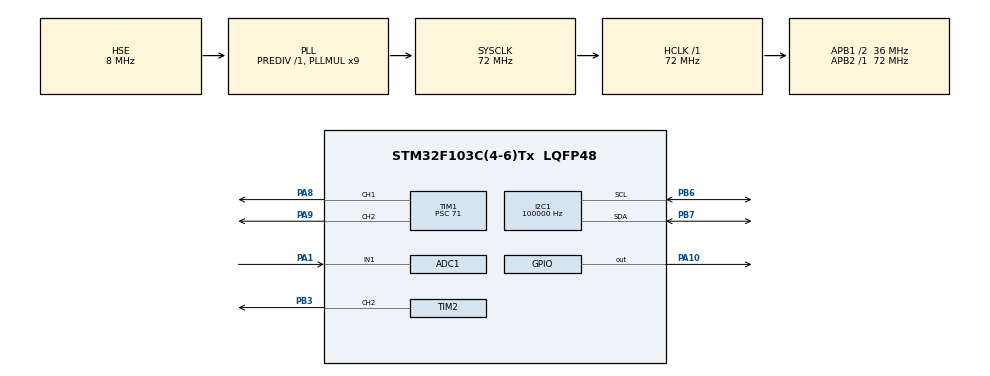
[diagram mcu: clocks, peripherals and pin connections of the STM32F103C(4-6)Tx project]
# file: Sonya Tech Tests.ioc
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ADC1.Channel-1\#ChannelRegularConversion=ADC_CHANNEL_1
ADC1.NbrOfConversionFlag=1
ADC1.Rank-1\#ChannelRegularConversion=1
ADC1.SamplingTime-1\#ChannelRegularConversion=ADC_SAMPLETIME_1CYCLE_5
ADC1.master=1
FREERTOS.Tasks01=GreenLed,-3,128,StartGreenLed,Default,NULL,Dynamic,NULL,NULL;Heater,2,128,HeaterFunction,Default,NULL,Dynamic,NULL,NULL;Cooler,0,128,CoolerFunction,Default,NULL,Dynamic,NULL,NULL
FREERTOS.configUSE_NEWLIB_REENTRANT=1
I2C1.ClockSpeed=100000
I2C1.I2C_Mode=I2C_Standard
Mcu.Family=STM32F1
Mcu.Name=STM32F103C(4-6)Tx
Mcu.Package=LQFP48
NVIC.PriorityGroup=NVIC_PRIORITYGROUP_4
NVIC.TIM3_IRQn=true\:15\:0\:false\:false\:true\:false\:false\:true\:true
NVIC.TimeBase=TIM3_IRQn
NVIC.TimeBaseIP=TIM3
PA1.Signal=ADCx_IN1
PA10.Signal=GPIO_Output
PA13.Mode=Serial_Wire
PA13.Signal=SYS_JTMS-SWDIO
PA14.Mode=Serial_Wire
PA14.Signal=SYS_JTCK-SWCLK
PA8.Signal=S_TIM1_CH1
PA9.Signal=S_TIM1_CH2
PB3.Signal=S_TIM2_CH2
PB6.GPIO_Pu=GPIO_NOPULL
PB6.Mode=I2C
PB6.Signal=I2C1_SCL
PB7.GPIO_Pu=GPIO_NOPULL
PB7.Mode=I2C
PB7.Signal=I2C1_SDA
PC14-OSC32_IN.Mode=LSE-External-Oscillator
PC14-OSC32_IN.Signal=RCC_OSC32_IN
PC15-OSC32_OUT.Mode=LSE-External-Oscillator
PC15-OSC32_OUT.Signal=RCC_OSC32_OUT
PD0-OSC_IN.Mode=HSE-External-Oscillator
PD0-OSC_IN.Signal=RCC_OSC_IN
PD1-OSC_OUT.Mode=HSE-External-Oscillator
PD1-OSC_OUT.Signal=RCC_OSC_OUT
ProjectManager.HeapSize=0x200
ProjectManager.StackSize=0x400
ProjectManager.TargetToolchain=STM32CubeIDE
RCC.ADCPresc=RCC_ADCPCLK2_DIV6
RCC.AHBFreq_Value=72000000
RCC.APB1CLKDivider=RCC_HCLK_DIV2
RCC.APB1Freq_Value=36000000
RCC.APB1TimFreq_Value=72000000
RCC.APB2Freq_Value=72000000
RCC.APB2TimFreq_Value=72000000
RCC.HCLKFreq_Value=72000000
RCC.PLLMUL=RCC_PLL_MUL9
RCC.PLLSourceVirtual=RCC_PLLSOURCE_HSE
RCC.SYSCLKFreq_VALUE=72000000
RCC.SYSCLKSource=RCC_SYSCLKSOURCE_PLLCLK
RCC.USBFreq_Value=72000000
SH.ADCx_IN1.0=ADC1_IN1,IN1
SH.S_TIM1_CH1.0=TIM1_CH1,PWM Generation1 CH1
SH.S_TIM1_CH2.0=TIM1_CH2,PWM Generation2 CH2
SH.S_TIM2_CH2.0=TIM2_CH2,PWM Generation2 CH2
TIM1.Channel-PWM\ Generation1\ CH1=TIM_CHANNEL_1
TIM1.Channel-PWM\ Generation2\ CH2=TIM_CHANNEL_2
TIM1.Period=99
TIM1.Prescaler=71
TIM2.Channel-PWM\ Generation2\ CH2=TIM_CHANNEL_2
TIM2.Period=99
TIM2.Prescaler=71
VP_FREERTOS_VS_CMSIS_V1.Mode=CMSIS_V1
VP_SYS_VS_tim3.Mode=TIM3
VP_TIM1_VS_ClockSourceINT.Mode=Internal
VP_TIM2_VS_ClockSourceINT.Mode=Internal
board=custom

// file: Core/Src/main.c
/* USER CODE BEGIN Header */
/**
  ******************************************************************************
  * @file           : main.c
  * @brief          : Main program body
  ******************************************************************************
  * @attention
  *
  * Copyright (c) 2025 STMicroelectronics.
  * All rights reserved.
  *
  * This software is licensed under terms that can be found in the LICENSE file
  * in the root directory of this software component.
  * If no LICENSE file comes with this software, it is provided AS-IS.
  *
  ******************************************************************************
  */
/* USER CODE END Header */
#include "main.h"
#include "cmsis_os.h"

/* USER CODE BEGIN Includes */

#include "heater.h"
#include "cooler.h"

/* USER CODE END Includes */

ADC_HandleTypeDef hadc1;

I2C_HandleTypeDef hi2c1;

TIM_HandleTypeDef htim1;
TIM_HandleTypeDef htim2;

osThreadId GreenLedHandle;
osThreadId HeaterHandle;
osThreadId CoolerHandle;

void SystemClock_Config(void);
static void MX_GPIO_Init(void);
static void MX_TIM1_Init(void);
static void MX_TIM2_Init(void);
static void MX_I2C1_Init(void);
static void MX_ADC1_Init(void);
void StartGreenLed(void const * argument);
void HeaterFunction(void const * argument);
void CoolerFunction(void const * argument);

int main(void)
{

  /* MCU Configuration--------------------------------------------------------*/

  /* Reset of all peripherals, Initializes the Flash interface and the Systick. */
  HAL_Init();

  /* Configure the system clock */
  SystemClock_Config();

  /* Initialize all configured peripherals */
  MX_GPIO_Init();
  MX_TIM1_Init();
  MX_TIM2_Init();
  MX_I2C1_Init();
  MX_ADC1_Init();

  /* Create the thread(s) */
  /* definition and creation of GreenLed */
  osThreadDef(GreenLed, StartGreenLed, osPriorityIdle, 0, 128);
  GreenLedHandle = osThreadCreate(osThread(GreenLed), NULL);

  /* definition and creation of Heater */
  osThreadDef(Heater, HeaterFunction, osPriorityHigh, 0, 128);
  HeaterHandle = osThreadCreate(osThread(Heater), NULL);

  /* definition and creation of Cooler */
  osThreadDef(Cooler, CoolerFunction, osPriorityNormal, 0, 128);
  CoolerHandle = osThreadCreate(osThread(Cooler), NULL);

  /* Start scheduler */
  osKernelStart();

  /* We should never get here as control is now taken by the scheduler */

  /* Infinite loop */
  while (1)
  {

  }
}

void SystemClock_Config(void)
{
  RCC_OscInitTypeDef RCC_OscInitStruct = {0};
  RCC_ClkInitTypeDef RCC_ClkInitStruct = {0};
  RCC_PeriphCLKInitTypeDef PeriphClkInit = {0};

  /** Initializes the RCC Oscillators according to the specified parameters
  * in the RCC_OscInitTypeDef structure.
  */
  RCC_OscInitStruct.OscillatorType = RCC_OSCILLATORTYPE_HSE;
  RCC_OscInitStruct.HSEState = RCC_HSE_ON;
  RCC_OscInitStruct.HSEPredivValue = RCC_HSE_PREDIV_DIV1;
  RCC_OscInitStruct.HSIState = RCC_HSI_ON;
  RCC_OscInitStruct.PLL.PLLState = RCC_PLL_ON;
  RCC_OscInitStruct.PLL.PLLSource = RCC_PLLSOURCE_HSE;
  RCC_OscInitStruct.PLL.PLLMUL = RCC_PLL_MUL9;
  if (HAL_RCC_OscConfig(&RCC_OscInitStruct) != HAL_OK)
  {
    Error_Handler();
  }

  /** Initializes the CPU, AHB and APB buses clocks
  */
  RCC_ClkInitStruct.ClockType = RCC_CLOCKTYPE_HCLK|RCC_CLOCKTYPE_SYSCLK
                              |RCC_CLOCKTYPE_PCLK1|RCC_CLOCKTYPE_PCLK2;
  RCC_ClkInitStruct.SYSCLKSource = RCC_SYSCLKSOURCE_PLLCLK;
  RCC_ClkInitStruct.AHBCLKDivider = RCC_SYSCLK_DIV1;
  RCC_ClkInitStruct.APB1CLKDivider = RCC_HCLK_DIV2;
  RCC_ClkInitStruct.APB2CLKDivider = RCC_HCLK_DIV1;

  if (HAL_RCC_ClockConfig(&RCC_ClkInitStruct, FLASH_LATENCY_2) != HAL_OK)
  {
    Error_Handler();
  }
  PeriphClkInit.PeriphClockSelection = RCC_PERIPHCLK_ADC;
  PeriphClkInit.AdcClockSelection = RCC_ADCPCLK2_DIV6;
  if (HAL_RCCEx_PeriphCLKConfig(&PeriphClkInit) != HAL_OK)
  {
    Error_Handler();
  }
}

static void MX_ADC1_Init(void)
{

  ADC_ChannelConfTypeDef sConfig = {0};

  /** Common config
  */
  hadc1.Instance = ADC1;
  hadc1.Init.ScanConvMode = ADC_SCAN_DISABLE;
  hadc1.Init.ContinuousConvMode = DISABLE;
  hadc1.Init.DiscontinuousConvMode = DISABLE;
  hadc1.Init.ExternalTrigConv = ADC_SOFTWARE_START;
  hadc1.Init.DataAlign = ADC_DATAALIGN_RIGHT;
  hadc1.Init.NbrOfConversion = 1;
  if (HAL_ADC_Init(&hadc1) != HAL_OK)
  {
    Error_Handler();
  }

  /** Configure Regular Channel
  */
  sConfig.Channel = ADC_CHANNEL_1;
  sConfig.Rank = ADC_REGULAR_RANK_1;
  sConfig.SamplingTime = ADC_SAMPLETIME_1CYCLE_5;
  if (HAL_ADC_ConfigChannel(&hadc1, &sConfig) != HAL_OK)
  {
    Error_Handler();
  }

}

static void MX_I2C1_Init(void)
{

  hi2c1.Instance = I2C1;
  hi2c1.Init.ClockSpeed = 100000;
  hi2c1.Init.DutyCycle = I2C_DUTYCYCLE_2;
  hi2c1.Init.OwnAddress1 = 0;
  hi2c1.Init.AddressingMode = I2C_ADDRESSINGMODE_7BIT;
  hi2c1.Init.DualAddressMode = I2C_DUALADDRESS_DISABLE;
  hi2c1.Init.OwnAddress2 = 0;
  hi2c1.Init.GeneralCallMode = I2C_GENERALCALL_DISABLE;
  hi2c1.Init.NoStretchMode = I2C_NOSTRETCH_DISABLE;
  if (HAL_I2C_Init(&hi2c1) != HAL_OK)
  {
    Error_Handler();
  }

}

static void MX_TIM1_Init(void)
{

  TIM_ClockConfigTypeDef sClockSourceConfig = {0};
  TIM_MasterConfigTypeDef sMasterConfig = {0};
  TIM_OC_InitTypeDef sConfigOC = {0};
  TIM_BreakDeadTimeConfigTypeDef sBreakDeadTimeConfig = {0};

  htim1.Instance = TIM1;
  htim1.Init.Prescaler = 71;
  htim1.Init.CounterMode = TIM_COUNTERMODE_UP;
  htim1.Init.Period = 99;
  htim1.Init.ClockDivision = TIM_CLOCKDIVISION_DIV1;
  htim1.Init.RepetitionCounter = 0;
  htim1.Init.AutoReloadPreload = TIM_AUTORELOAD_PRELOAD_DISABLE;
  if (HAL_TIM_Base_Init(&htim1) != HAL_OK)
  {
    Error_Handler();
  }
  sClockSourceConfig.ClockSource = TIM_CLOCKSOURCE_INTERNAL;
  if (HAL_TIM_ConfigClockSource(&htim1, &sClockSourceConfig) != HAL_OK)
  {
    Error_Handler();
  }
  if (HAL_TIM_PWM_Init(&htim1) != HAL_OK)
  {
    Error_Handler();
  }
  sMasterConfig.MasterOutputTrigger = TIM_TRGO_RESET;
  sMasterConfig.MasterSlaveMode = TIM_MASTERSLAVEMODE_DISABLE;
  if (HAL_TIMEx_MasterConfigSynchronization(&htim1, &sMasterConfig) != HAL_OK)
  {
    Error_Handler();
  }
  sConfigOC.OCMode = TIM_OCMODE_PWM1;
  sConfigOC.Pulse = 0;
  sConfigOC.OCPolarity = TIM_OCPOLARITY_HIGH;
  sConfigOC.OCNPolarity = TIM_OCNPOLARITY_HIGH;
  sConfigOC.OCFastMode = TIM_OCFAST_DISABLE;
  sConfigOC.OCIdleState = TIM_OCIDLESTATE_RESET;
  sConfigOC.OCNIdleState = TIM_OCNIDLESTATE_RESET;
  if (HAL_TIM_PWM_ConfigChannel(&htim1, &sConfigOC, TIM_CHANNEL_1) != HAL_OK)
  {
    Error_Handler();
  }
  if (HAL_TIM_PWM_ConfigChannel(&htim1, &sConfigOC, TIM_CHANNEL_2) != HAL_OK)
  {
    Error_Handler();
  }
  sBreakDeadTimeConfig.OffStateRunMode = TIM_OSSR_DISABLE;
  sBreakDeadTimeConfig.OffStateIDLEMode = TIM_OSSI_DISABLE;
  sBreakDeadTimeConfig.LockLevel = TIM_LOCKLEVEL_OFF;
  sBreakDeadTimeConfig.DeadTime = 0;
  sBreakDeadTimeConfig.BreakState = TIM_BREAK_DISABLE;
  sBreakDeadTimeConfig.BreakPolarity = TIM_BREAKPOLARITY_HIGH;
  sBreakDeadTimeConfig.AutomaticOutput = TIM_AUTOMATICOUTPUT_DISABLE;
  if (HAL_TIMEx_ConfigBreakDeadTime(&htim1, &sBreakDeadTimeConfig) != HAL_OK)
  {
    Error_Handler();
  }
  HAL_TIM_MspPostInit(&htim1);

}

static void MX_TIM2_Init(void)
{

  TIM_ClockConfigTypeDef sClockSourceConfig = {0};
  TIM_MasterConfigTypeDef sMasterConfig = {0};
  TIM_OC_InitTypeDef sConfigOC = {0};

  htim2.Instance = TIM2;
  htim2.Init.Prescaler = 71;
  htim2.Init.CounterMode = TIM_COUNTERMODE_UP;
  htim2.Init.Period = 99;
  htim2.Init.ClockDivision = TIM_CLOCKDIVISION_DIV1;
  htim2.Init.AutoReloadPreload = TIM_AUTORELOAD_PRELOAD_DISABLE;
  if (HAL_TIM_Base_Init(&htim2) != HAL_OK)
  {
    Error_Handler();
  }
  sClockSourceConfig.ClockSource = TIM_CLOCKSOURCE_INTERNAL;
  if (HAL_TIM_ConfigClockSource(&htim2, &sClockSourceConfig) != HAL_OK)
  {
    Error_Handler();
  }
  if (HAL_TIM_PWM_Init(&htim2) != HAL_OK)
  {
    Error_Handler();
  }
  sMasterConfig.MasterOutputTrigger = TIM_TRGO_RESET;
  sMasterConfig.MasterSlaveMode = TIM_MASTERSLAVEMODE_DISABLE;
  if (HAL_TIMEx_MasterConfigSynchronization(&htim2, &sMasterConfig) != HAL_OK)
  {
    Error_Handler();
  }
  sConfigOC.OCMode = TIM_OCMODE_PWM1;
  sConfigOC.Pulse = 0;
  sConfigOC.OCPolarity = TIM_OCPOLARITY_HIGH;
  sConfigOC.OCFastMode = TIM_OCFAST_DISABLE;
  if (HAL_TIM_PWM_ConfigChannel(&htim2, &sConfigOC, TIM_CHANNEL_2) != HAL_OK)
  {
    Error_Handler();
  }
  HAL_TIM_MspPostInit(&htim2);

}

static void MX_GPIO_Init(void)
{
  GPIO_InitTypeDef GPIO_InitStruct = {0};

  /* GPIO Ports Clock Enable */
  __HAL_RCC_GPIOC_CLK_ENABLE();
  __HAL_RCC_GPIOD_CLK_ENABLE();
  __HAL_RCC_GPIOA_CLK_ENABLE();
  __HAL_RCC_GPIOB_CLK_ENABLE();

  /*Configure GPIO pin Output Level */
  HAL_GPIO_WritePin(GPIOA, GPIO_PIN_10, GPIO_PIN_RESET);

  /*Configure GPIO pin : PA10 */
  GPIO_InitStruct.Pin = GPIO_PIN_10;
  GPIO_InitStruct.Mode = GPIO_MODE_OUTPUT_PP;
  GPIO_InitStruct.Pull = GPIO_NOPULL;
  GPIO_InitStruct.Speed = GPIO_SPEED_FREQ_LOW;
  HAL_GPIO_Init(GPIOA, &GPIO_InitStruct);

}

void StartGreenLed(void const * argument)
{
  for(;;)
  {
  }
}

void HeaterFunction(void const * argument)
{
  /* USER CODE BEGIN HeaterFunction */
  /* Infinite loop */
  for(;;)
  {
	  heaterOn(&hi2c1, &htim1);  //uses temp sensor
    /**
	      HAL_GPIO_WritePin(GPIOA, GPIO_PIN_8,1);   //PWM pin for heater
	  	  HAL_GPIO_WritePin(GPIOA, GPIO_PIN_9, 1);
	  	  TIM1->CCR1 = 50;				//Select the write channel for pin
	  	  TIM1->CCR2 = 50;
	  	  //TIM1->CCR1 = 0;
	  	  HAL_TIM_PWM_Start(&htim1, TIM_CHANNEL_1);  //Select the write channel for pin
	  	  HAL_TIM_PWM_Start(&htim1, TIM_CHANNEL_2);

        */

  }
  /* USER CODE END HeaterFunction */
}

void CoolerFunction(void const * argument)
{
  /* USER CODE BEGIN CoolerFunction */
  /* Infinite loop */
  for(;;)
  {
	  coolerOn(&htim2, &hadc1);
  }
  /* USER CODE END CoolerFunction */
}

void HAL_TIM_PeriodElapsedCallback(TIM_HandleTypeDef *htim)
{
  if (htim->Instance == TIM3) {
    HAL_IncTick();
  }
}

void Error_Handler(void)
{
  __disable_irq();
  while (1)
  {
  }
}
